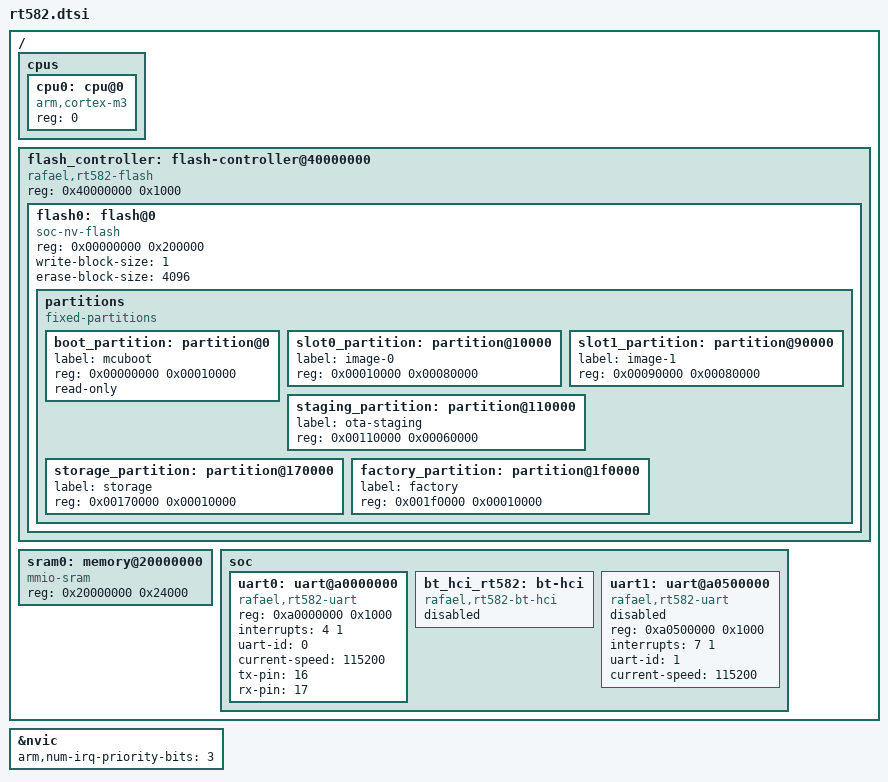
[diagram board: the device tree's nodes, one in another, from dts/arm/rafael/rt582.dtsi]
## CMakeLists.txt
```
cmake_minimum_required(VERSION 3.20.0)

set(BOARD_ROOT   ${CMAKE_CURRENT_LIST_DIR})
set(SOC_ROOT     ${CMAKE_CURRENT_LIST_DIR})
set(DTS_ROOT     ${CMAKE_CURRENT_LIST_DIR})
set(KCONFIG_ROOT ${CMAKE_CURRENT_LIST_DIR}/Kconfig)

# Register this repo as a Zephyr module so cmake/zephyr_serial/CMakeLists.txt
# is add_subdirectory'd at the correct point in Zephyr's build (after
# drivers__serial is created, before the empty-library check).
list(APPEND ZEPHYR_EXTRA_MODULES ${CMAKE_CURRENT_SOURCE_DIR})

find_package(Zephyr REQUIRED HINTS $ENV{ZEPHYR_BASE})
project(rt583_helloworld VERSION 1.1.1)

# ── Build metadata ────────────────────────────────────────────────────────────
execute_process(
    COMMAND git rev-parse --short HEAD
    WORKING_DIRECTORY ${CMAKE_CURRENT_SOURCE_DIR}
    OUTPUT_VARIABLE BUILD_GIT_HASH
    OUTPUT_STRIP_TRAILING_WHITESPACE
    ERROR_QUIET
)
if(NOT BUILD_GIT_HASH)
    set(BUILD_GIT_HASH "unknown")
endif()

execute_process(
    COMMAND git status --porcelain
    WORKING_DIRECTORY ${CMAKE_CURRENT_SOURCE_DIR}
    OUTPUT_VARIABLE GIT_DIRTY_OUTPUT
    OUTPUT_STRIP_TRAILING_WHITESPACE
    ERROR_QUIET
)
if(GIT_DIRTY_OUTPUT)
    string(APPEND BUILD_GIT_HASH "+dirty")
endif()

target_compile_definitions(app PRIVATE
    BUILD_GIT_HASH="${BUILD_GIT_HASH}"
)

# Make tprintk.h findable by SDK source files via #include "tprintk.h"
target_include_directories(app PRIVATE ${CMAKE_CURRENT_SOURCE_DIR}/examples/thread/src)

# Rafael IoT SDK vendored into sdk/.
set(RAFAEL_SDK ${CMAKE_CURRENT_LIST_DIR}/sdk)
set(RT583_PLATFORM ${RAFAEL_SDK}/components/platform)

# Application source
target_sources(app PRIVATE examples/thread/src/main.c)

# ── OpenThread ────────────────────────────────────────────────────────────────
if(CONFIG_OPENTHREAD_RT583)
    include(subsys/openthread/CMakeLists.txt)
endif()

# ── RT583 platform drivers ────────────────────────────────────────────────────
# Platform sources (system_mcu.c, sysctrl.c, etc.) and include directories are
# now provided by cmake/zephyr_module/CMakeLists.txt via ZEPHYR_EXTRA_MODULES,
# so they are available to both this app and MCUboot without duplication.
set(RT583_DRV_SRC ${RT583_PLATFORM}/soc/rt583/rt583_driver/Src)

target_include_directories(app PRIVATE
    ${RT583_PLATFORM}/soc/rt583/rt583_driver/Inc
    ${RT583_PLATFORM}/soc/rt583/rt583_system/Include
    ${RT583_PLATFORM}/hosal/rt583_hosal/Inc
)

# comm_subsystem_drv.c is only needed by the Thread example.
target_sources(app PRIVATE
    ${RT583_DRV_SRC}/comm_subsystem_drv.c
)

# ── RT583 UART driver ─────────────────────────────────────────────────────────
# uart_rt583.c + hosal_uart.c are added to drivers__serial via the Zephyr
# module cmake at cmake/zephyr_serial/CMakeLists.txt (see zephyr/module.yml).
# ZEPHYR_EXTRA_MODULES above registers this repo as a module so that cmake
# runs at the correct point in Zephyr's build graph.
```

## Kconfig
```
# Top-level Kconfig for rt583-zephyr-helloworld.
# Zephyr's Kconfig tree is sourced first, then we add our custom driver.

osource "$(ZEPHYR_BASE)/Kconfig"

# Driver Kconfigs are loaded via Kconfig.module (zephyr/module.yml),
# so they must NOT be rsourced here to avoid duplicate symbol definitions.

# OTA subsystem
rsource "subsys/ota/Kconfig"

# OpenThread — extend Zephyr's OPENTHREAD_IMPLEMENTATION choice with the RT583 option.
# When OPENTHREAD_RT583 is selected, CONFIG_OPENTHREAD_SOURCES=n so Zephyr does NOT
# compile modules/lib/openthread core or its platform stubs (entropy.c, radio.c …).
# Our subsys/openthread/CMakeLists.txt compiles the SDK OT from source instead.
choice OPENTHREAD_IMPLEMENTATION
    default OPENTHREAD_RT583 if SOC_RT583
    default OPENTHREAD_RT584 if SOC_RT584
config OPENTHREAD_RT583
    bool "Rafael RT583 SDK OpenThread"
    depends on SOC_RT583 && OPENTHREAD
    help
      Build OpenThread from the vendored Rafael IoT SDK sources in sdk/.
      Provides FTD functionality with hardware-backed radio, TRNG, and
      Cortex-M3 alarm via the RT583 HOSAL/LMAC15P4 layer.
      Replaces Zephyr's modules/lib/openthread and its platform stubs.

config OPENTHREAD_RT584
    bool "Rafael RT584 SDK OpenThread"
    depends on SOC_RT584 && OPENTHREAD
    help
      RT584 OpenThread port — same SDK glue as RT583 (lmac15p4 / RUCI /
      ot_radio.c are SoC-agnostic) but pulls rt569-rf/rt584/ + rt569-fw
      /rt584/ instead.
endchoice

# Both rt583 and rt584 use the same lmac15p4 / RUCI stack, so the PIB
# defaults are identical. Keep the RT583_ prefix for the Kconfig symbols
# to avoid breaking existing build configurations.
if OPENTHREAD_RT583 || OPENTHREAD_RT584

menu "Rafael IEEE 802.15.4 PHY/MAC PIB"

config RT583_PHY_PIB_TURNAROUND_TIMER
    int "PHY turnaround time (symbols)"
    default 192

config RT583_PHY_PIB_CCA_DETECTED_TIME
    int "PHY CCA detected time (symbols)"
    default 128

config RT583_PHY_PIB_CCA_DETECT_MODE
    int "PHY CCA detection mode (0=ED, 1=CS, 2=ED+CS)"
    default 0
    range 0 2

config RT583_PHY_PIB_CCA_THRESHOLD
    int "PHY CCA energy threshold"
    default 85

config RT583_MAC_PIB_UNIT_BACKOFF_PERIOD
    int "MAC unit backoff period (symbols)"
    default 320

config RT583_MAC_PIB_ACK_WAIT_DURATION
    int "MAC ACK wait duration (symbols)"
    default 544

config RT583_MAC_PIB_MAX_BE
    int "MAC maximum backoff exponent"
    default 8
    range 0 8

config RT583_MAC_PIB_MAX_FRAME_TOTAL_WAIT_TIME
    int "MAC max frame total wait time (symbols)"
    default 16416

config RT583_MAC_PIB_MAX_FRAME_RETRIES
    int "MAC max frame retries"
    default 4
    range 0 7

config RT583_MAC_PIB_MAX_CSMACA_BACKOFFS
    int "MAC max CSMA-CA backoffs"
    default 10
    range 0 10

config RT583_MAC_PIB_MIN_BE
    int "MAC minimum backoff exponent"
    default 5
    range 0 8

endmenu

config RT583_RF_FW_EXPECTED_CRC32
    hex "Expected CRC32 of RF firmware blob (0 = log only, no check)"
    default 0x0
    help
      CRC32 (IEEE) of firmware_program_ruci[]. When non-zero, the firmware
      blob is verified at boot. Set to 0 to print the CRC without checking.
      Run once with 0, read the log, then set this value to lock it down.

endif # OPENTHREAD_RT583 || OPENTHREAD_RT584

# Matter application options
if CHIP

config RT583_CRYPTO_SELFTEST
    bool "Run hardware crypto self-test at boot"
    default y
    help
      Runs AES-128-ECB, AES-128-CBC, and HMAC-SHA256 Known-Answer Tests
      against the RT583 hardware crypto accelerator during AppTask::Init().
      Disable for production to save ~2 KB flash and ~50 ms boot time.

config RT583_HEAP_TRACE
    bool "Enable per-alloc/free heap trace output"
    default n
    help
      Compiles in chip_heap_enable_trace() and per-allocation printk trace
      in MallocWrappers.cpp. When disabled, trace code is compiled out and
      chip_heap_enable_trace() is a no-op stub.

endif # CHIP

# BLE — same SDK glue, just different RF MCU sources / hosal_rf path
# per SoC. Enable BLE_RT583 when building for SOC_RT583, BLE_RT584 for
# SOC_RT584. The HCI driver (drivers/bluetooth/hci_rt583.c) is
# SoC-agnostic; it talks to the COMM_SUBSYSTEM via hosal_rf.
config BLE_RT583
    bool "Bluetooth LE for Rafael RT583"
    depends on SOC_RT583
    default y if SOC_RT583 && BT
    select BT_HCI_SETUP if BT
    help
      Enables the BLE stack on the RT583 SoC via the integrated
      BLE controller firmware and Zephyr's BLE host stack.

config BLE_RT584
    bool "Bluetooth LE for Rafael RT584"
    depends on SOC_RT584
    default y if SOC_RT584 && BT
    select BT_HCI_SETUP if BT
    help
      RT584 BLE port — same SDK glue as RT583 (hci_rt583.c is generic,
      pulls hosal_rf / rf_mcu / RUCI / RF firmware via the rt584 SoC
      subtree).
```

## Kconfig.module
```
# Kconfig.module — RT583 out-of-tree driver Kconfigs
#
# Sourced by Zephyr's module system (zephyr/module.yml kconfig: entry).
# This makes UART_RT583 and FLASH_RT583 visible to any app or bootloader
# that uses this module, including MCUboot.

rsource "drivers/serial/Kconfig"
rsource "drivers/flash/Kconfig"
rsource "drivers/bluetooth/Kconfig"
rsource "drivers/entropy/Kconfig"
rsource "drivers/ieee802154/Kconfig"

# MCUboot's Kconfig defines MBEDTLS_CONFIG_FILE without a type (it expects
# Zephyr's mbedTLS Kconfig to provide the 'string' declaration first).
# If our module is loaded before mbedTLS, kconfiglib warns "defined without
# a type" and Zephyr aborts. Pre-declare the type here to silence the warning.
config MBEDTLS_CONFIG_FILE
    string
```

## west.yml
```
manifest:
  version: "0.13"

  defaults:
    remote: zephyrproject

  remotes:
    - name: zephyrproject
      url-base: https://github.com/zephyrproject-rtos
    - name: mcuboot
      url-base: https://github.com/mcu-tools
    - name: matter
      url-base: https://github.com/project-chip

  projects:
    - name: zephyr
      revision: v4.4.0-rc1
      west-commands: scripts/west-commands.yml
    - name: cmsis
      revision: 512cc7e895e8491696b61f7ba8066b4a182569b8
      path: modules/hal/cmsis
    - name: cmsis_6
      repo-path: CMSIS_6
      revision: 30a859f44ef8ab4dc8f84b03ed586fd16ccf9d74
      path: modules/hal/cmsis_6
    - name: mbedtls
      revision: 26158d1c012477e77765d138b26a791db917c881
      path: modules/crypto/mbedtls
    - name: tf-psa-crypto
      revision: 6820f1dadc67c289d2dc63aec495519c9d589d8e
      path: modules/crypto/mbedtls/tf-psa-crypto
    - name: openthread
      revision: e4d97681c53ec1cc34af1404ad2960adda4ba691
      path: modules/lib/openthread

    - name: mcuboot
      remote: mcuboot
      revision: cf5810201c84d6e266aeda2abdab80854066ac08
      path: bootloader/mcuboot

    - name: connectedhomeip
      remote: matter
      revision: fdb31dbcb3ebe000ad3e41b386e90849937948f9
      path: connectedhomeip
      import: false

  self:
    path: zephyr-thread-rt58x
    west-commands: scripts/west-commands.yml
```

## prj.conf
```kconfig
# RT583-EVB Zephyr + OpenThread CLI

CONFIG_SERIAL=y
CONFIG_CONSOLE=y
CONFIG_UART_CONSOLE=y
CONFIG_UART_RT583=y
CONFIG_UART_INTERRUPT_DRIVEN=y

CONFIG_PRINTK=y
CONFIG_THREAD_NAME=y

CONFIG_PICOLIBC=y
CONFIG_HEAP_MEM_POOL_SIZE=32768

CONFIG_MAIN_STACK_SIZE=2048

CONFIG_CPP=y
CONFIG_STD_CPP14=y

# Shell disabled — competes with printk on UART TX causing corrupted output
# CONFIG_SHELL=y
# CONFIG_SHELL_BACKEND_SERIAL=y
# CONFIG_SHELL_STACK_SIZE=2048

CONFIG_OPENTHREAD_RT583=y

CONFIG_CRC=y

CONFIG_ISR_STACK_SIZE=2048

# System workqueue — needed for k_work_submit (watchdog + UART TX simulation)
CONFIG_SYSTEM_WORKQUEUE_STACK_SIZE=2048

# Flash driver (required for MCUboot and OTA)
CONFIG_FLASH=y
CONFIG_FLASH_RT583=y
CONFIG_FLASH_PAGE_LAYOUT=y
CONFIG_FLASH_MAP=y

# MCUboot integration (Direct XIP)
CONFIG_BOOTLOADER_MCUBOOT=y
CONFIG_MCUBOOT_BOOTLOADER_MODE_DIRECT_XIP=y

# OTA subsystem — version must match CMakeLists.txt project(VERSION x.y.z)
CONFIG_OTA=y
CONFIG_OTA_CURRENT_VERSION_MAJOR=1
CONFIG_OTA_CURRENT_VERSION_MINOR=1
CONFIG_OTA_CURRENT_VERSION_PATCH=1
```

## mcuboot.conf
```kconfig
# MCUboot configuration for RT583-EVB (Direct XIP + ECDSA P-256)
#
# Build MCUboot:
#   west build -b rt583_evb bootloader/mcuboot/boot/zephyr \
#     -- -DOVERLAY_CONFIG=<project-path>/mcuboot.conf
#
# Flash MCUboot to 0x0, app to slot0 (0x10000) or slot1 (0xD0000).

# ── Upgrade strategy: Direct XIP ─────────────────────────────────────────
# MCUboot selects the newest valid image and executes it directly from
# its flash slot. No swap, no copy, no scratch partition needed.
# Both slots must contain images linked for their respective addresses.
CONFIG_BOOT_DIRECT_XIP=y

# ── Signature: ECDSA P-256 ───────────────────────────────────────────────
# Same curve as Rafael SDK secure boot — key format compatible.
# Generate key:  imgtool keygen -k mcuboot-ec256.pem -t ecdsa-p256
# Sign image:    west sign -t imgtool -- --key mcuboot-ec256.pem
CONFIG_BOOT_SIGNATURE_TYPE_ECDSA_P256=y
CONFIG_BOOT_SIGNATURE_KEY_FILE="mcuboot-ec256.pem"

# ── Validate primary slot on every boot ──────────────────────────────────
# Ensures tampered/corrupted images are never executed.
CONFIG_BOOT_VALIDATE_SLOT0=y

# ── Flash driver ─────────────────────────────────────────────────────────
CONFIG_FLASH=y
CONFIG_FLASH_RT583=y
CONFIG_FLASH_PAGE_LAYOUT=y
CONFIG_FLASH_MAP=y

# ── Serial console (MCUboot debug output) ────────────────────────────────
CONFIG_SERIAL=y
CONFIG_UART_CONSOLE=y
CONFIG_UART_RT583=y
CONFIG_CONSOLE=y
CONFIG_PRINTK=y

# ── Size optimization (fit in 64 KB boot partition) ──────────────────────
CONFIG_SIZE_OPTIMIZATIONS=y
CONFIG_MCUBOOT_LOG_LEVEL_WRN=y
CONFIG_BOOT_BANNER=n
CONFIG_MAIN_STACK_SIZE=2048
CONFIG_MBEDTLS_CFG_FILE="mcuboot-mbedtls-cfg.h"
```

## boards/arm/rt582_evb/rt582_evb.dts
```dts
/*
 * Device tree for Rafael RT582 EVB
 */

/dts-v1/;
#include <arm/rafael/rt582.dtsi>

/ {
    model = "Rafael Microelectronics RT582 EVB";
    compatible = "rafael,rt582-evb", "rafael,rt582";

    chosen {
        zephyr,sram             = &sram0;
        zephyr,flash            = &flash0;
        zephyr,flash-controller = &flash_controller;
        zephyr,console          = &uart0;
        zephyr,shell-uart       = &uart0;
        zephyr,code-partition   = &slot0_partition;
        zephyr,bt-hci           = &bt_hci_rt582;
    };
};

&bt_hci_rt582 {
    status = "okay";
};
```

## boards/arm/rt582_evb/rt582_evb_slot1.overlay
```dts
/*
 * RT582-EVB slot1 overlay
 *
 * 將 zephyr,code-partition 指向 slot1_partition（0x90000），
 * 使 image 被 linked 並執行於 0x90000。
 * 搭配 MCUboot Direct XIP：MCUboot 比較版本後從 slot1 直接執行。
 */
/ {
    chosen {
        zephyr,code-partition = &slot1_partition;
    };
};
```

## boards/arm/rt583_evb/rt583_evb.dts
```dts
/*
 * Device tree for Rafael RT583 EVB
 */

/dts-v1/;
#include <arm/rafael/rt583.dtsi>

/ {
    model = "Rafael Microelectronics RT583 EVB";
    compatible = "rafael,rt583-evb", "rafael,rt583";

    chosen {
        zephyr,sram             = &sram0;
        zephyr,flash            = &flash0;
        zephyr,flash-controller = &flash_controller;
        zephyr,console          = &uart0;
        zephyr,shell-uart       = &uart0;
        zephyr,code-partition   = &slot0_partition;
        zephyr,bt-hci           = &bt_hci_rt583;
        zephyr,ieee802154       = &ieee802154_rt583;
        zephyr,entropy          = &trng;
    };
};

&bt_hci_rt583 {
    status = "okay";
};
```

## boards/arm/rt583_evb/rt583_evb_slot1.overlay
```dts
/*
 * RT583-EVB slot1 overlay
 *
 * 將 zephyr,code-partition 指向 slot1_partition（0x90000），
 * 使 image 被 linked 並執行於 0x90000。
 * 搭配 MCUboot Direct XIP：MCUboot 比較版本後從 slot1 直接執行。
 */
/ {
    chosen {
        zephyr,code-partition = &slot1_partition;
    };
};
```

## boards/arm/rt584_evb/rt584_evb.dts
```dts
/*
 * Device tree for Rafael RT584 EVB
 */

/dts-v1/;
#include <arm/rafael/rt584.dtsi>

/ {
    model = "Rafael Microelectronics RT584 EVB";
    compatible = "rafael,rt584-evb", "rafael,rt584";

    chosen {
        zephyr,sram             = &sram0;
        zephyr,flash            = &flash0;
        zephyr,flash-controller = &flash_controller;
        zephyr,console          = &uart0;
        zephyr,shell-uart       = &uart0;
        zephyr,code-partition   = &slot0_partition;
        zephyr,entropy          = &trng;
        zephyr,bt-hci           = &bt_hci_rt584;
        zephyr,ieee802154       = &ieee802154_rt584;
    };
};

&bt_hci_rt584 {
    status = "okay";
};
```

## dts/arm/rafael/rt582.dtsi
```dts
/*
 * RT582 SoC device tree include (ARM Cortex-M3)
 *
 * Memory map sourced from:
 *   components/platform/soc/rt582/rt582_driver/Inc/mcu.h
 *   components/platform/soc/rt582/rt582_evb/evb/ld/rt582.ld
 *
 * PERIPH_BASE  = 0x40000000
 * PERIPH_BASE2 = 0xA0000000  (UART, COMM_SUBSYSTEM)
 *
 * IRQ numbers (from mcu.h IRQn_Type enum):
 *   Uart0_IRQn = 4
 *   Uart1_IRQn = 7
 *   Uart2_IRQn = 19
 */

#include <arm/armv7-m.dtsi>

/ {
    cpus {
        #address-cells = <1>;
        #size-cells = <0>;

        cpu0: cpu@0 {
            compatible = "arm,cortex-m3";
            reg = <0>;
        };
    };

    /*
     * RT582 flash layout (from rt582.ld LMA regions):
     *   0x00000000  BOOT  32 KB   (bootloader)
     *   0x00008000  CORE  928 KB  (main application)
     *   0x000F0000  USER  32 KB
     *   0x000F0800  MP    32 KB
     *
     * For a standalone Zephyr image we occupy the full 1 MB.
     */
    flash_controller: flash-controller@40000000 {
        compatible = "rafael,rt582-flash";
        reg = <0x40000000 0x1000>;
        #address-cells = <1>;
        #size-cells = <1>;

        flash0: flash@0 {
            compatible = "soc-nv-flash";
            reg = <0x00000000 0x200000>;    /* 2 MB */
            write-block-size = <1>;
            erase-block-size = <4096>;

            partitions {
                compatible = "fixed-partitions";
                #address-cells = <1>;
                #size-cells = <1>;

                /*
                 * Direct XIP layout (2 MB flash):
                 *
                 *   0x000000  boot       64 KB  MCUboot
                 *   0x010000  slot0     512 KB  App primary   (Direct XIP)
                 *   0x090000  slot1     512 KB  App secondary (Direct XIP)
                 *   0x110000  staging   384 KB  OTA compressed download buffer
                 *   0x170000  storage    64 KB  NVS / OpenThread dataset
                 *   0x180000  (gap)      96 KB  reserved
                 *   0x1F0000  factory    64 KB  MP sector / factory data
                 *
                 * Slot size 512 KB; LZ4 compression ~40% → ~307 KB < 384 KB ✓
                 * MCUboot selects the newest valid image and jumps directly —
                 * no swap, no copy to RAM.
                 * Slot 0 and Slot 1 must be identical size.
                 */

                /* MCUboot bootloader: 64 KB */
                boot_partition: partition@0 {
                    label = "mcuboot";
                    reg = <0x00000000 0x00010000>;
                    read-only;
                };

                /* Primary image slot: 512 KB */
                slot0_partition: partition@10000 {
                    label = "image-0";
                    reg = <0x00010000 0x00080000>;
                };

                /* Secondary image slot: 512 KB (Direct XIP — equal to slot 0) */
                slot1_partition: partition@90000 {
                    label = "image-1";
                    reg = <0x00090000 0x00080000>;
                };

                /* OTA compressed image staging: 384 KB
                 * Receives LZ4-compressed image before decompressing to slot1.
                 * 512 KB app × ~60% LZ4 output ≈ 307 KB — fits with margin. */
                staging_partition: partition@110000 {
                    label = "ota-staging";
                    reg = <0x00110000 0x00060000>;
                };

                /* NV storage (OpenThread settings, Zephyr NVS): 64 KB */
                storage_partition: partition@170000 {
                    label = "storage";
                    reg = <0x00170000 0x00010000>;
                };

                /* MP sector + factory data: 64 KB (flash 末段) */
                factory_partition: partition@1f0000 {
                    label = "factory";
                    reg = <0x001f0000 0x00010000>;
                };
            };
        };
    };

    sram0: memory@20000000 {
        compatible = "mmio-sram";
        /* 144 KB = 0x24000 (from VMA_DATA + VMA_STACK in rt582.ld) */
        reg = <0x20000000 0x24000>;
    };

    soc {
        /*
         * UART0 – stdio console
         *   Base : PERIPH_BASE2        = 0xA0000000
         *   IRQ  : Uart0_IRQn         = 4
         *   Pins : TX=GPIO16, RX=GPIO17 (from default-rt582-evb.config)
         *   Baud : 115200
         */
        uart0: uart@a0000000 {
            compatible = "rafael,rt582-uart";
            reg = <0xa0000000 0x1000>;
            interrupts = <4 1>;
            uart-id = <0>;
            current-speed = <115200>;
            tx-pin = <16>;
            rx-pin = <17>;
            status = "okay";
        };

        /*
         * UART1
         *   Base : PERIPH_BASE2 + 0x500000 = 0xA0500000
         *   IRQ  : Uart1_IRQn = 7
         */
        bt_hci_rt582: bt-hci {
            compatible = "rafael,rt582-bt-hci";
            status = "disabled";
        };

        uart1: uart@a0500000 {
            compatible = "rafael,rt582-uart";
            reg = <0xa0500000 0x1000>;
            interrupts = <7 1>;
            uart-id = <1>;
            current-speed = <115200>;
            status = "disabled";
        };
    };
};

/* RT582 Cortex-M3 NVIC: 3 priority bits (__NVIC_PRIO_BITS = 3 in mcu.h) */
&nvic {
    arm,num-irq-priority-bits = <3>;
};

/* Point the Zephyr console at UART0. */
&uart0 {
    status = "okay";
};
```

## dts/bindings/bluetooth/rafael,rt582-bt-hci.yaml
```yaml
description: Rafael RT582 integrated BLE controller (HCI over shared memory)

compatible: "rafael,rt582-bt-hci"

include: bt-hci.yaml

properties:
  bt-hci-name:
    default: "RT582 BLE"
  bt-hci-bus:
    default: "virtual"
  bt-hci-quirks:
    default: ["no-reset"]
```

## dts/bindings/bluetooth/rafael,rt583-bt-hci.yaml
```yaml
description: Rafael RT583 integrated BLE controller (HCI over shared memory)

compatible: "rafael,rt583-bt-hci"

include: bt-hci.yaml

properties:
  bt-hci-name:
    default: "RT583 BLE"
  bt-hci-bus:
    default: "virtual"
  bt-hci-quirks:
    default: ["no-reset"]
```

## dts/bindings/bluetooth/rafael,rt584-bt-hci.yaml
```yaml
description: Rafael RT584 integrated Bluetooth LE controller (HCI over COMM_SUBSYSTEM)

compatible: "rafael,rt584-bt-hci"

include: bt-hci.yaml

properties:
  bt-hci-name:
    default: "RT584 BLE"
  bt-hci-bus:
    default: "virtual"
  bt-hci-quirks:
    default: ["no-reset"]
```

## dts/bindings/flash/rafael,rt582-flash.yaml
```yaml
description: Rafael RT582 internal SPI flash controller

compatible: "rafael,rt582-flash"

include: base.yaml

properties:
  reg:
    required: true
  "#address-cells":
    const: 1
  "#size-cells":
    const: 1
```

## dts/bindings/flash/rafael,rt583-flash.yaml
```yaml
description: Rafael RT583 internal SPI flash controller

compatible: "rafael,rt583-flash"

include: base.yaml

properties:
  reg:
    required: true
  "#address-cells":
    const: 1
  "#size-cells":
    const: 1
```

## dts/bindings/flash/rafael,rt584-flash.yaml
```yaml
description: Rafael RT584 internal SPI flash controller

compatible: "rafael,rt584-flash"

include: base.yaml

properties:
  reg:
    required: true
  "#address-cells":
    const: 1
  "#size-cells":
    const: 1
```

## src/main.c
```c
/*
 * main.c — RT582-EVB Zephyr + OpenThread CLI
 *
 * RULE: Never call printk from a k_timer expiry or any ISR.
 * k_timer expiry runs in SysTick ISR context. printk holds a spinlock;
 * if the main thread is also inside printk the ISR will spin forever
 * (single-core deadlock). Use k_work_submit to defer to thread context.
 */

#include <zephyr/kernel.h>
#include <zephyr/sys/printk.h>
#include <zephyr/sys/crc.h>
#include "tprintk.h"

#include <openthread/cli.h>
#include <openthread/instance.h>

#include "openthread_port.h"
#include "hosal_rf.h"
#include "lmac15p4.h"

/* RF firmware blob — verify integrity before loading */
extern const uint8_t  firmware_program_ruci[];
extern const uint32_t firmware_size_ruci;

extern volatile uint32_t rt582_comm_irq_count;
extern volatile uint32_t ot_uart_rx_byte_count;
extern volatile uint32_t ot_uart_isr_count;
extern volatile uint32_t ot_uart_line_count;

/* ── Watchdog: dedicated thread (independent of system workqueue) ────────── *
 * k_msleep-based — does not rely on k_timer/k_work/system workqueue.        *
 * If this prints but k_work version does not → workqueue stack overflow.    *
 * If this does not print → scheduler not running (IRQs blocked).            */
#define WDOG_STACK_SIZE 1024
K_THREAD_STACK_DEFINE(wdog_stack, WDOG_STACK_SIZE);
static struct k_thread wdog_thread_data;
static uint32_t        wdog_tick;

static void wdog_thread_fn(void *p1, void *p2, void *p3)
{
    ARG_UNUSED(p1); ARG_UNUSED(p2); ARG_UNUSED(p3);
    while (1) {
        k_msleep(200);
        wdog_tick++;
    }
}

/* PIB values — configured via Kconfig (RT582 IEEE 802.15.4 PHY/MAC PIB menu) */
#define PHY_PIB_TURNAROUND_TIMER          CONFIG_RT582_PHY_PIB_TURNAROUND_TIMER
#define PHY_PIB_CCA_DETECTED_TIME         CONFIG_RT582_PHY_PIB_CCA_DETECTED_TIME
#define PHY_PIB_CCA_DETECT_MODE           CONFIG_RT582_PHY_PIB_CCA_DETECT_MODE
#define PHY_PIB_CCA_THRESHOLD             CONFIG_RT582_PHY_PIB_CCA_THRESHOLD
#define MAC_PIB_UNIT_BACKOFF_PERIOD       CONFIG_RT582_MAC_PIB_UNIT_BACKOFF_PERIOD
#define MAC_PIB_MAC_ACK_WAIT_DURATION     CONFIG_RT582_MAC_PIB_ACK_WAIT_DURATION
#define MAC_PIB_MAC_MAX_BE                CONFIG_RT582_MAC_PIB_MAX_BE
#define MAC_PIB_MAC_MAX_FRAME_TOTAL_WAIT_TIME CONFIG_RT582_MAC_PIB_MAX_FRAME_TOTAL_WAIT_TIME
#define MAC_PIB_MAC_MAX_FRAME_RETRIES     CONFIG_RT582_MAC_PIB_MAX_FRAME_RETRIES
#define MAC_PIB_MAC_MAX_CSMACA_BACKOFFS   CONFIG_RT582_MAC_PIB_MAX_CSMACA_BACKOFFS
#define MAC_PIB_MAC_MIN_BE                CONFIG_RT582_MAC_PIB_MIN_BE

void otrInitUser(otInstance *instance)
{
    otAppCliInit(instance);
}

int main(void)
{
    (printk)("======================================\n");
    (printk)("  RT582-EVB  Zephyr + OpenThread CLI  \n");
    (printk)("  Built: " __DATE__ " " __TIME__ "  \n");
    (printk)("  Hash:  " BUILD_GIT_HASH "          \n");
    (printk)("======================================\n");

    k_thread_create(&wdog_thread_data, wdog_stack, K_THREAD_STACK_SIZEOF(wdog_stack),
                    wdog_thread_fn, NULL, NULL, NULL,
                    2, 0, K_NO_WAIT);
    k_thread_name_set(&wdog_thread_data, "wdog");

    printk("[MAIN] wdog started");

    /* Verify RF firmware blob integrity before loading */
    if (firmware_size_ruci > 0) {
        uint32_t fw_crc = crc32_ieee(firmware_program_ruci, firmware_size_ruci);
        printk("[RF] firmware CRC32: 0x%08x (size=%u)", fw_crc, firmware_size_ruci);
#if CONFIG_RT582_RF_FW_EXPECTED_CRC32 != 0
        if (fw_crc != CONFIG_RT582_RF_FW_EXPECTED_CRC32) {
            printk("[RF] ERROR: firmware CRC mismatch! expected=0x%08x",
                   CONFIG_RT582_RF_FW_EXPECTED_CRC32);
        }
#endif
    }

    printk("[RF] hosal_rf_init...");
    hosal_rf_init(HOSAL_RF_MODE_RUCI_CMD);
    printk("[RF] hosal_rf_init done");

    printk("[RF] lmac15p4_init...");
    lmac15p4_init(LMAC15P4_2P4G_OQPSK, 0);
    printk("[RF] lmac15p4_init done");

    lmac15p4_phy_pib_set(PHY_PIB_TURNAROUND_TIMER, PHY_PIB_CCA_DETECT_MODE,
                         PHY_PIB_CCA_THRESHOLD, PHY_PIB_CCA_DETECTED_TIME);
    lmac15p4_mac_pib_set(MAC_PIB_UNIT_BACKOFF_PERIOD,
                         MAC_PIB_MAC_ACK_WAIT_DURATION, MAC_PIB_MAC_MAX_BE,
                         MAC_PIB_MAC_MAX_CSMACA_BACKOFFS,
                         MAC_PIB_MAC_MAX_FRAME_TOTAL_WAIT_TIME,
                         MAC_PIB_MAC_MAX_FRAME_RETRIES, MAC_PIB_MAC_MIN_BE);
    printk("[RF] PIB set done");

    otrStart();
    printk("OpenThread FTD task started.");

    return 0;
}
```

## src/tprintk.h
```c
#pragma once

/*
 * tprintk.h — redefine printk to prepend millisecond uptime timestamp.
 *
 * Include AFTER <zephyr/kernel.h> (or any header that pulls it in).
 * k_uptime_get_32() must already be declared.
 *
 * Output format:  [  1234] [TAG] message
 *
 * To emit raw output (no timestamp) at a specific call site, write:
 *   (printk)("raw line\n");   <- parentheses bypass the macro
 *
 * ISR guard: __ASSERT_NO_MSG(!k_is_in_isr()) catches ISR-context printk
 * at runtime. Single-core Cortex-M3 will deadlock on printk's spinlock
 * if the main thread is also inside printk when the ISR fires.
 */
#undef printk
#define printk(fmt, ...) \
    do { \
        __ASSERT_NO_MSG(!k_is_in_isr()); \
        (printk)("[%7u] " fmt " [%s:%d]\n", \
                 k_uptime_get_32(), ##__VA_ARGS__, __FILE_NAME__, __LINE__); \
    } while (0)
```
